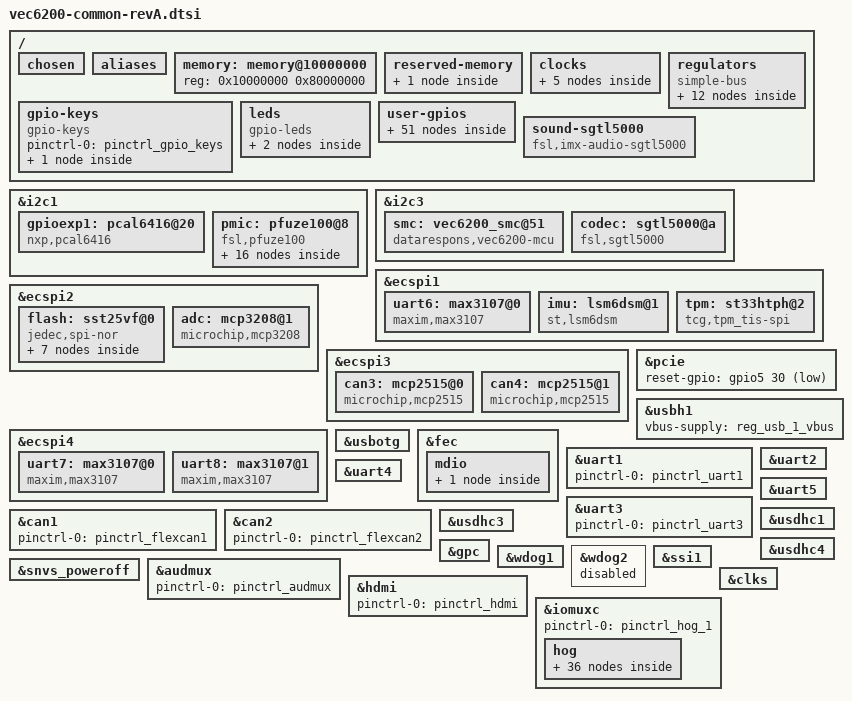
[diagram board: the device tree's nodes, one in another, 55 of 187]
/*
 * Copyright 2020 Data Respons Solutions AB
 *
 * The code contained herein is licensed under the GNU General Public
 * License. You may obtain a copy of the GNU General Public License
 * Version 2 or later at the following locations:
 *
 * http://www.opensource.org/licenses/gpl-license.html
 * http://www.gnu.org/copyleft/gpl.html
 */

#include <dt-bindings/gpio/gpio.h>
#include <dt-bindings/input/input.h>

// Issues:
// uart6 missing interrupt - must be patched
// uart6 missing reset - ok?
// flash: 8Mbit not enought --> Minimum 16Mbit. Preferred 32Mbit.
// GP_VGA_nRESET not connected

/ {	
	chosen {
		stdout-path = "serial0:115200n8";
		bootargs = "loglevel=6";
	};
	
	aliases {
		serial5 = &uart6;
		serial6 = &uart7;
		serial7 = &uart8;
		rtc0 = &smc;
		rtc1 = &snvs_rtc;
		can2 = &can3;
		can3 = &can4;
	};
	
	memory: memory@10000000 {
		reg = <0x10000000 0x80000000>;
	};
	
	reserved-memory {
		#address-cells = <1>;
		#size-cells = <1>;
		ranges;

		// Etnaviv driver requires cma region
		linux,cma {
			compatible = "shared-dma-pool";
			reusable;
			size = <0x10000000>;
			linux,cma-default;
		};
	};
	
	clocks {
		uart6_clk: osc_uart6 {
			compatible = "fixed-clock";
			#clock-cells = <0>;
			clock-frequency = <3686400>;
		};
		
		uart7_clk: osc_uart7 {
			compatible = "fixed-clock";
			#clock-cells = <0>;
			clock-frequency = <3686400>;
		};
		
		uart8_clk: osc_uart8 {
			compatible = "fixed-clock";
			#clock-cells = <0>;
			clock-frequency = <3686400>;
		};
				
		can3_clk: osc_can3 {
			compatible = "fixed-clock";
			#clock-cells = <0>;
			clock-frequency = <20000000>;
		};
		
		can4_clk: osc_can4 {
			compatible = "fixed-clock";
			#clock-cells = <0>;
			clock-frequency = <20000000>;
		};
	};
	
	regulators {
		compatible = "simple-bus";

		reg_3v3_io: 3v3_io {
			compatible = "regulator-fixed";
			regulator-name = "3v3_io";
			regulator-min-microvolt = <3300000>;
			regulator-max-microvolt = <3300000>;
		};
		
		reg_5v_io: 5v_io {
			compatible = "regulator-fixed";
			regulator-name = "5v_io";
			regulator-min-microvolt = <5000000>;
			regulator-max-microvolt = <5000000>;
		};
		
		reg_adc_vref: adc_vref {
			compatible = "regulator-fixed";
			regulator-name = "adc_vref";
			regulator-min-microvolt = <2500000>;
			regulator-max-microvolt = <2500000>;
		};
		
		reg_usb_otg_vbus: usb_otg_vbus {
			compatible = "regulator-fixed";
			pinctrl-names = "default";
			pinctrl-0 = <&pinctrl_reg_usbotg>;
			regulator-name = "usb_otg_vbus";
			regulator-min-microvolt = <5000000>;
			regulator-max-microvolt = <5000000>;
			gpio = <&gpio3 30 GPIO_ACTIVE_HIGH>;
			enable-active-high;
		};

		reg_usb_1_vbus: usb_1_vbus {
			compatible = "regulator-fixed";
			pinctrl-names = "default";
			pinctrl-0 = <&pinctrl_reg_usb1>;
			regulator-name = "usb_1_vbus";
			regulator-min-microvolt = <5000000>;
			regulator-max-microvolt = <5000000>;
			gpio = <&gpio2 0 GPIO_ACTIVE_HIGH>;
			enable-active-high;
		};
		
		reg_gps: gps {
			compatible = "regulator-fixed";
			pinctrl-names = "default";
			pinctrl-0 = <&pinctrl_reg_gps>;
			regulator-name = "gps";
			regulator-min-microvolt = <3300000>;
			regulator-max-microvolt = <3300000>;
			gpio = <&gpio2 1 GPIO_ACTIVE_HIGH>;
			enable-active-high;
			regulator-always-on;
		};
		
		reg_codec: codec {
			compatible = "regulator-fixed";
			pinctrl-names = "default";
			pinctrl-0 = <&pinctrl_reg_codec>;
			regulator-name = "codec";
			regulator-min-microvolt = <1800000>;
			regulator-max-microvolt = <1800000>;
			gpio = <&gpio6 14 GPIO_ACTIVE_HIGH>;
			enable-active-high;
		};
			
		reg_wifi: wifi {
			compatible = "regulator-fixed";
			pinctrl-names = "default";
			pinctrl-0 = <&pinctrl_reg_wifi>;
			regulator-name = "wifi";
			regulator-min-microvolt = <3300000>;
			regulator-max-microvolt = <3300000>;
			gpio = <&gpio2 2 GPIO_ACTIVE_HIGH>;
			enable-active-high;
		};
		
		reg_wifi_en: wifi_en {
			compatible = "regulator-fixed";
			pinctrl-names = "default";
			pinctrl-0 = <&pinctrl_reg_wifi_en>;
			regulator-name = "wifi_en";
			regulator-min-microvolt = <3300000>;
			regulator-max-microvolt = <3300000>;
			gpio = <&gpio2 3 GPIO_ACTIVE_HIGH>;
			enable-active-high;
			vin-supply = <&reg_wifi>;
		};
		
		reg_bt_en: bt_en {
			compatible = "regulator-fixed";
			pinctrl-names = "default";
			pinctrl-0 = <&pingctrl_reg_bt_en>;
			regulator-name = "bt_en";
			regulator-min-microvolt = <3300000>;
			regulator-max-microvolt = <3300000>;
			gpio = <&gpio2 4 GPIO_ACTIVE_HIGH>;
			enable-active-high;
			vin-supply = <&reg_wifi>;
		};
		
		reg_hdmi: hdmi {
			compatible = "regulator-fixed";
			pinctrl-names = "default";
			pinctrl-0 = <&pinctrl_reg_hdmi>;
			regulator-name = "hdmi";
			regulator-min-microvolt = <5000000>;
			regulator-max-microvolt = <5000000>;
			gpio = <&gpio6 11 GPIO_ACTIVE_HIGH>;
			enable-active-high;
			regulator-always-on;
		};
		
		reg_gps_antenna: gps_antenna {
			compatible = "regulator-fixed";
			pinctrl-names = "default";
			pinctrl-0 = <&pinctrl_reg_gps_antenna>;
			regulator-name = "gps_antenna";
			regulator-min-microvolt = <5000000>;
			regulator-max-microvolt = <5000000>;
			gpio = <&gpio6 15 GPIO_ACTIVE_HIGH>;
			enable-active-high;
			regulator-always-on;
		};
	};
	
	gpio-keys {
		compatible = "gpio-keys";
		pinctrl-names = "default";
		pinctrl-0 = <&pinctrl_gpio_keys>;

		power {
			label = "Power Button";
			gpios = <&gpio3 29 GPIO_ACTIVE_LOW>;
			gpio-key,wakeup;
			linux,code = <KEY_POWER>;
		};
	};
	
	leds {
		compatible = "gpio-leds";
		
		status-green {
			label = "status-green";
			gpios = <&gpioexp1 10 GPIO_ACTIVE_HIGH>;
		};
	
		status-red {
			label = "status-red";
			gpios = <&gpioexp1 11 GPIO_ACTIVE_HIGH>;
		};
	};

	user-gpios {	
		digital_input_1 {
			gpios = <&gpio1 1 GPIO_ACTIVE_HIGH>;
			status = "okay";
		};
		
		digital_input_2 {
			gpios = <&gpio1 2 GPIO_ACTIVE_HIGH>;
			status = "okay";
		};
		
		digital_input_3 {
			gpios = <&gpio1 5 GPIO_ACTIVE_HIGH>;
			status = "okay";
		};
		
		digital_input_4 {
			gpios = <&gpio1 6 GPIO_ACTIVE_HIGH>;
			status = "okay";
		};
		
		digital_output_sink_1 {
			gpios = <&gpio4 26 GPIO_ACTIVE_HIGH>;
			status = "okay";
			value = <0>;
		};
		
		digital_output_sink_2 {
			gpios = <&gpio4 27 GPIO_ACTIVE_HIGH>;
			status = "okay";
			value = <0>;
		};
		
		digital_output_sink_3 {
			gpios = <&gpio4 28 GPIO_ACTIVE_HIGH>;
			status = "okay";
			value = <0>;
		};

		digital_output_sink_4 {
			gpios = <&gpio4 29 GPIO_ACTIVE_HIGH>;
			status = "okay";
			value = <0>;
		};
		
		digital_output_sink_5 {
			gpios = <&gpio5 16 GPIO_ACTIVE_HIGH>;
			status = "okay";
			value = <0>;
		};
		
		digital_output_sink_6 {
			gpios = <&gpio5 17 GPIO_ACTIVE_HIGH>;
			status = "okay";
			value = <0>;
		};
		
		analog_input_1_mode {
			gpios = <&gpio1 15 GPIO_ACTIVE_HIGH>;
			status = "okay";
			value = <0>;
		};
		
		analog_input_2_mode {
			gpios = <&gpio1 14 GPIO_ACTIVE_HIGH>;
			status = "okay";
			value = <0>;
		};
		
		analog_input_3_mode {
			gpios = <&gpio1 13 GPIO_ACTIVE_HIGH>;
			status = "okay";
			value = <0>;
		};
		
		analog_input_4_mode {
			gpios = <&gpio1 12 GPIO_ACTIVE_HIGH>;
			status = "okay";
			value = <0>;
		};
		
		mcu-boot0 {
			gpios = <&gpio4 17 GPIO_ACTIVE_HIGH>;
			status = "okay";
			value = <0>;
		};
		
		mcu-status {
			gpios = <&gpio4 31 GPIO_ACTIVE_HIGH>;
			status = "okay";
			value = <0>;
		};

		mcu-reset {
			gpios = <&gpio1 4 GPIO_ACTIVE_HIGH>;
			status = "okay";
			value = <0>;
		};
		
        usb_hub_rst {
        	gpios = <&gpio7 13 GPIO_ACTIVE_LOW>;
        	status = "okay";
        	value = <0>;
		};
		
		tpm_rst {
			gpios = <&gpio4 8 GPIO_ACTIVE_LOW>;
			status = "okay";
			value = <0>;
		};
		
		flash_wp {
			gpios = <&gpio5 6 GPIO_ACTIVE_LOW>;
			status = "okay";
			value = <1>;
		};
		
		buck_5v_en {
			gpios = <&gpio5 31 GPIO_ACTIVE_HIGH>;
			status = "okay";
			value = <0>;
		};
		
		can1_en {
			gpios = <&gpioexp1 12 GPIO_ACTIVE_HIGH>;
			status = "okay";
			value = <0>;
		};

		can1_wake {
			gpios = <&gpio4 18 GPIO_ACTIVE_HIGH>;
			status = "okay";
			value = <0>;
		};
	
		can1_stb {
			gpios = <&gpio1 27 GPIO_ACTIVE_LOW>;
			status = "okay";
			value = <0>;
		};
		
		can1_err {
			gpios = <&gpioexp1 2 GPIO_ACTIVE_LOW>;
			status = "okay";
		};
		
		can1_res_en {
			gpios = <&gpio3 31 GPIO_ACTIVE_HIGH>;
			status = "okay";
			value = <0>;
		};
		
		can2_en {
			gpios = <&gpioexp1 13 GPIO_ACTIVE_HIGH>;
			status = "okay";
			value = <0>;
		};
		
		can2_wake {
			gpios = <&gpio4 19 GPIO_ACTIVE_HIGH>;
			status = "okay";
			value = <0>;
		};
	
		can2_stb {
			gpios = <&gpio4 10 GPIO_ACTIVE_LOW>;
			status = "okay";
			value = <0>;
		};
		
		can2_err {
			gpios = <&gpioexp1 3 GPIO_ACTIVE_LOW>;
			status = "okay";
		};
		
		can2_res_en {
			gpios = <&gpio1 9 GPIO_ACTIVE_HIGH>;
			status = "okay";
			value = <0>;
		};
		
		can3_en {
			gpios = <&gpioexp1 14 GPIO_ACTIVE_HIGH>;
			status = "okay";
			value = <0>;
		};
		
		can3_wake {
			gpios = <&gpio5 19 GPIO_ACTIVE_HIGH>;
			status = "okay";
			value = <0>;
		};
	
		can3_stb {
			gpios = <&gpio4 30 GPIO_ACTIVE_LOW>;
			status = "okay";
			value = <0>;
		};
		
		can3_err {
			gpios = <&gpioexp1 4 GPIO_ACTIVE_LOW>;
			status = "okay";
		};
		
		can3_res_en {
			gpios = <&gpio1 30 GPIO_ACTIVE_HIGH>;
			status = "okay";
			value = <0>;
		};
		
		can3_rst {
			gpios = <&gpio4 20 GPIO_ACTIVE_LOW>;
			status = "okay";
			value = <0>;
		};
		
		can4_en {
			gpios = <&gpioexp1 15 GPIO_ACTIVE_HIGH>;
			status = "okay";
			value = <0>;
		};
		
		can4_wake {
			gpios = <&gpio5 18 GPIO_ACTIVE_HIGH>;
			status = "okay";
			value = <0>;
		};
	
		can4_stb {
			gpios = <&gpio5 5 GPIO_ACTIVE_LOW>;
			status = "okay";
			value = <0>;
		};
		
		can4_err {
			gpios = <&gpioexp1 5 GPIO_ACTIVE_LOW>;
			status = "okay";
		};
		
		can4_res_en {
			gpios = <&gpio4 5 GPIO_ACTIVE_HIGH>;
			status = "okay";
			value = <0>;
		};
		
		can4_rst {
			gpios = <&gpio3 23 GPIO_ACTIVE_LOW>;
			status = "okay";
			value = <0>;
		};
		
		odometer {
			gpios = <&gpioexp1 0 GPIO_ACTIVE_HIGH>;
			status = "okay";
		};
		
		forward {
			gpios = <&gpioexp1 1 GPIO_ACTIVE_LOW>;
			status = "okay";
		};
		
		modem_rst {
			gpios = <&gpioexp1 6 GPIO_ACTIVE_LOW>;
			status = "okay";
			value = <0>;
		};
		
		modem_disable {
			gpios = <&gpioexp1 7 GPIO_ACTIVE_LOW>;
			status = "okay";
			value = <0>;
		};
		
		uart7_res_en {
			gpios = <&gpioexp1 8 GPIO_ACTIVE_HIGH>;
			status = "okay";
			value = <0>;
		};
		
		uart7_rst {
			gpios = <&gpio2 23 GPIO_ACTIVE_LOW>;
			status = "okay";
			value = <0>;
		};
		
		uart8_res_en {
			gpios = <&gpioexp1 9 GPIO_ACTIVE_HIGH>;
			status = "okay";
			value = <0>;
		};
		
		uart8_rst {
			gpios = <&gpio2 24 GPIO_ACTIVE_LOW>;
			status = "okay";
			value = <0>;
		};
	};

	sound-sgtl5000 {
		compatible = "fsl,imx-audio-sgtl5000";
		model = "sgtl5000";
		ssi-controller = <&ssi1>;
		audio-codec = <&codec>;
		audio-routing =
			"MIC_IN", "Mic Jack",
			"Mic Jack", "Mic Bias",
			"Line Out Jack", "LINE_OUT",
			"LINE_IN", "Line In Jack";
		mux-int-port = <1>;
		mux-ext-port = <3>;
	};
#if 0
	ch7036-lvds0 {
		compatible = "chrontel,ch7036", "panel-lvds";
		data-mapping = "jeida-24";

		width-mm = <410>; // Mandatory attribute and random googled value
		height-mm = <230>; // Mandatory attribute and random googled value
		panel-timing {
			/* 1366x768 @60Hz */
			clock-frequency = <76000000>;
			hactive = <1366>;
			vactive = <768>;
			hsync-len = <64>;
			hfront-porch = <32>;
			hback-porch = <98>;
			vsync-len = <12>;
			vfront-porch = <6>;
			vback-porch = <20>;
			hsync-active = <0>;
			vsync-active = <0>;
			de-active = <1>;
		};
			
		port {
			ch7036_in: endpoint {
				remote-endpoint = <&lvds0_out>;
			};
		};
	};
#endif
};

&i2c1 {
	clock-frequency = <100000>;
	pinctrl-names = "default", "gpio";
	pinctrl-0 = <&pinctrl_i2c1>;
	pinctrl-1 = <&pinctrl_i2c1_gpio>;
	scl-gpios = <&gpio5 27 (GPIO_ACTIVE_LOW|GPIO_OPEN_DRAIN)>;
	sda-gpios = <&gpio5 26 (GPIO_ACTIVE_LOW|GPIO_OPEN_DRAIN)>;
	status = "okay";

	gpioexp1: pcal6416@20 {
		compatible = "nxp,pcal6416";
		reg = <0x20>;
		pinctrl-names = "default";
		pinctrl-0 = <&pinctrl_pcal6416>;
		interrupt-parent = <&gpio2>;
		interrupts = <5 IRQ_TYPE_EDGE_FALLING>;
		reset-gpios = <&gpio2 7 GPIO_ACTIVE_LOW>;
		interrupt-controller;
		#interrupt-cells = <2>;
		gpio-controller;
		#gpio-cells = <2>;
	};
	
	pmic: pfuze100@8 {
		compatible = "fsl,pfuze100";
		reg = <0x08>;
		pinctrl-names = "default";
		pinctrl-0 = <&pinctrl_pmic>;
		interrupt-parent = <&gpio6>;
		interrupts = <10 IRQ_TYPE_EDGE_FALLING>;

		regulators {
			sw1a_reg: sw1ab {
				regulator-min-microvolt = <300000>;
				regulator-max-microvolt = <1875000>;
				regulator-boot-on;
				regulator-always-on;
				regulator-ramp-delay = <6250>;
			};

			sw1c_reg: sw1c {
				regulator-min-microvolt = <300000>;
				regulator-max-microvolt = <1875000>;
				regulator-boot-on;
				regulator-always-on;
				regulator-ramp-delay = <6250>;
			};

			sw2_reg: sw2 {
				regulator-min-microvolt = <800000>;
				regulator-max-microvolt = <3300000>;
				regulator-boot-on;
				regulator-always-on;
				regulator-ramp-delay = <6250>;
			};

			sw3a_reg: sw3a {
				regulator-min-microvolt = <400000>;
				regulator-max-microvolt = <1975000>;
				regulator-boot-on;
				regulator-always-on;
			};

			sw3b_reg: sw3b {
				regulator-min-microvolt = <400000>;
				regulator-max-microvolt = <1975000>;
				regulator-boot-on;
				regulator-always-on;
			};

			sw4_reg: sw4 {
				regulator-min-microvolt = <800000>;
				regulator-max-microvolt = <3300000>;
			};

			swbst_reg: swbst {
				regulator-min-microvolt = <5000000>;
				regulator-max-microvolt = <5150000>;
			};

			snvs_reg: vsnvs {
				regulator-min-microvolt = <1000000>;
				regulator-max-microvolt = <3000000>;
				regulator-boot-on;
				regulator-always-on;
			};

			vref_reg: vrefddr {
				regulator-boot-on;
				regulator-always-on;
			};

			vgen1_reg: vgen1 {
				regulator-min-microvolt = <800000>;
				regulator-max-microvolt = <1550000>;
			};

			vgen2_reg: vgen2 {
				regulator-min-microvolt = <800000>;
				regulator-max-microvolt = <1550000>;
			};

			vgen3_reg: vgen3 {
				regulator-min-microvolt = <1800000>;
				regulator-max-microvolt = <3300000>;
			};

			vgen4_reg: vgen4 {
				regulator-min-microvolt = <1800000>;
				regulator-max-microvolt = <3300000>;
				regulator-always-on;
			};

			vgen5_reg: vgen5 {
				regulator-min-microvolt = <1800000>;
				regulator-max-microvolt = <3300000>;
				regulator-always-on;
			};

			vgen6_reg: vgen6 {
				regulator-min-microvolt = <1800000>;
				regulator-max-microvolt = <3300000>;
				regulator-always-on;
			};
		};
	};
};

&i2c3 {
	clock-frequency = <100000>;
	pinctrl-names = "default", "gpio";
	pinctrl-0 = <&pinctrl_i2c3>;
	pinctrl-1 = <&pinctrl_i2c3_gpio>;
	scl-gpios = <&gpio1 3 (GPIO_ACTIVE_LOW|GPIO_OPEN_DRAIN)>;
	sda-gpios = <&gpio7 11 (GPIO_ACTIVE_LOW|GPIO_OPEN_DRAIN)>;
	status = "okay";

	smc: vec6200_smc@51 {
		compatible = "datarespons,vec6200-mcu";
		reg = <0x51>;
		interrupt-parent = <&gpio5>;
		interrupts = <15 IRQ_TYPE_EDGE_FALLING>;
		//FIXME: additional GPIO
		smc-gpio-names = "gpio_dc_on", "gpio_can_on", "gpi_ignition", "gpi_wakeup";
		smc-gpio-input = <0 0 1 1>;
		has-rtc;
	};
	
	codec: sgtl5000@a {
		compatible = "fsl,sgtl5000";
		reg = <0x0a>;
		#sound-dai-cells = <0>;
		clocks = <&clks IMX6QDL_CLK_CKO>;
		micbias-resistor-k-ohms = <2>;
		micbias-voltage-m-volts = <1250>;
		VDDA-supply = <&reg_3v3_io>;
		VDDIO-supply = <&reg_3v3_io>;
		VDDD-supply = <&reg_codec>;
	};
	
	//FIXME: CH7036
};

&ecspi1 {
	fsl,cpi-num-chipselects = <3>;
	cs-gpios = 	<&gpio2 25 GPIO_ACTIVE_LOW>,
				<&gpio3 19 GPIO_ACTIVE_LOW>,
				<&gpio4 11 GPIO_ACTIVE_LOW>;
	pinctrl-names = "default";
	pinctrl-0 = <&pinctrl_ecspi1>;
	status = "okay";
	
	uart6: max3107@0 {
		compatible = "maxim,max3107";
		reg = <0>;
		spi-max-frequency = <26000000>;
		clocks = <&uart6_clk>;
		clock-names = "osc";
		//interrupt-parent = <&gpio3>; //FIXME: NO IRQ
		//interrupts = <7 IRQ_TYPE_LEVEL_LOW>;
	};
	
	imu: lsm6dsm@1 {
		reg = <1>;
		compatible = "st,lsm6dsm";
		spi-max-frequency = <10000000>;
		interrupt-parent = <&gpio5>;
		interrupts = <7 IRQ_TYPE_EDGE_RISING>, <8 IRQ_TYPE_EDGE_RISING>;
	};
	
	tpm: st33htph@2 {
		reg = <2>;
		compatible = "tcg,tpm_tis-spi";
		spi-max-frequency = <10000000>;
		interrupt-parent = <&gpio5>;
		interrupts = <14 IRQ_TYPE_EDGE_FALLING>;
	};
};

&ecspi2 {
	fsl,spi-num-chipselects = <2>;
	cs-gpios =	<&gpio5 12 GPIO_ACTIVE_LOW>,
				<&gpio5 9 GPIO_ACTIVE_LOW>;
	pinctrl-names = "default";
	pinctrl-0 = <&pinctrl_ecspi2>;
	status = "okay";

	flash: sst25vf@0 {
		#address-cells = <1>;
		compatible = "jedec,spi-nor";
		spi-max-frequency = <25000000>;
		reg = <0>;
		
		partitions {
			compatible = "fixed-partitions";
			#address-cells = <1>;
			#size-cells = <1>;
			
			spl@0 {
				label = "spl";
				reg = <0x0 0x20000>;
			};
			
			u-boot@20000 {
				label = "u-boot";
				reg = <0x20000 0x90000>;
			};
		
			system_a@B0000 {
				label = "system_a";
				reg = <0xB0000 0x10000>;
			};
			
			system_b@C0000 {
				label = "system_b";
				reg = <0xC0000 0x10000>;
			};
				
			user_a@D0000 {
				label = "user_a";
				reg = <0xD0000 0x10000>;
			};
			
			user_b@E0000 {
				label = "user_b";
				reg = <0xE0000 0x10000>;
			};
		};
	};
	
	adc: mcp3208@1 {
		reg = <1>;
		compatible = "microchip,mcp3208";
		spi-max-frequency = <1000000>;
		vref-supply = <&reg_adc_vref>;
	};
};

&ecspi3 {
	fsl,cpi-num-chipselects = <2>;
	cs-gpios = 	<&gpio4 24 GPIO_ACTIVE_LOW>,
				<&gpio4 25 GPIO_ACTIVE_LOW>;
	pinctrl-names = "default";
	pinctrl-0 = <&pinctrl_ecspi3>;
	status = "okay";
	
	can3: mcp2515@0 {
		compatible = "microchip,mcp2515";
		spi-max-frequency = <10000000>;
		reg = <0>;
		clocks = <&can3_clk>;
		interrupt-parent = <&gpio3>;
		interrupts = <26 IRQ_TYPE_EDGE_FALLING>;
		vdd-supply = <&reg_5v_io>;
		xceiver-supply = <&reg_5v_io>;
	};
	
	can4: mcp2515@1 {
		compatible = "microchip,mcp2515";
		spi-max-frequency = <10000000>;
		reg = <1>;
		clocks = <&can4_clk>;
		interrupt-parent = <&gpio3>;
		interrupts = <27 IRQ_TYPE_EDGE_FALLING>;
		vdd-supply = <&reg_5v_io>;
		xceiver-supply = <&reg_5v_io>;
	};
};

&ecspi4 {
	fsl,cpi-num-chipselects = <2>;
	cs-gpios = 	<&gpio3 20 GPIO_ACTIVE_LOW>,
				<&gpio5 2 GPIO_ACTIVE_LOW>;
	pinctrl-names = "default";
	pinctrl-0 = <&pinctrl_ecspi4>;
	status = "okay";
	
	uart7: max3107@0 {
		compatible = "maxim,max3107";
		reg = <0>;
		spi-max-frequency = <26000000>;
		clocks = <&uart7_clk>;
		clock-names = "osc";
		interrupt-parent = <&gpio1>;
		interrupts = <11 IRQ_TYPE_EDGE_FALLING>;
	};
	
	uart8: max3107@1 {
		compatible = "maxim,max3107";
		reg = <1>;
		spi-max-frequency = <26000000>;
		clocks = <&uart8_clk>;
		clock-names = "osc";
		interrupt-parent = <&gpio1>;
		interrupts = <10 IRQ_TYPE_EDGE_FALLING>;
	};
};

&pcie {
	reset-gpio = <&gpio5 30 GPIO_ACTIVE_LOW>;
	status = "okay";
};

&usbh1 {
	vbus-supply = <&reg_usb_1_vbus>;
	status = "okay";		
};

&usbotg {
	vbus-supply = <&reg_usb_otg_vbus>;
	pinctrl-names = "default";
	pinctrl-0 = <&pinctrl_usbotg>;
	vbus-supply = <&reg_usb_otg_vbus>;
	over-current-active-low;
	status = "okay";
};

&fec {
	pinctrl-names = "default";
	pinctrl-0 = <&pinctrl_enet0>;
	phy-mode = "rgmii";
	status = "okay";
	
	phy-handle = <&enet0_phy>;
	
	mdio {
		#address-cells = <1>;
		#size-cells = <0>;
		
		enet0_phy: ar8033@0 {
			compatible = "ethernet-phy-ieee802.3-c22";
			reg = <0>;
			max-speed = <100>;
			interrupt-parent = <&gpio1>;
			interrupts = <26 IRQ_TYPE_EDGE_FALLING>;
		};
	};
};

&uart1 {
	pinctrl-names = "default";
	pinctrl-0 = <&pinctrl_uart1>;
	status = "okay";
};

&uart2 {
	pinctrl-names = "default";
	pinctrl-0 = <&pinctrl_uart2>;
	uart-has-rtscts;
	status = "okay";
};

&uart3 {
	pinctrl-names = "default";
	pinctrl-0 = <&pinctrl_uart3>;
	status = "okay";
};

&uart4 {
	pinctrl-names = "default";
	pinctrl-0 = <&pinctrl_uart4>;
	uart-has-rtscts;
	status = "okay";
};

&uart5 {
	pinctrl-names = "default";
	pinctrl-0 = <&pinctrl_uart5>;
	uart-has-rtscts;
	status = "okay";
};

&can1 {
	pinctrl-names = "default";
	pinctrl-0 = <&pinctrl_flexcan1>;
	status = "okay";
};

&can2 {
	pinctrl-names = "default";
	pinctrl-0 = <&pinctrl_flexcan2>;
	status = "okay";
};

&usdhc1 {
	pinctrl-names = "default";
	pinctrl-0 = <&pinctrl_usdhc1>;
	bus-width = <4>;
	broken-cd;
	no-1-8-v;
	keep-power-in-suspend;
	enable-sdio-wakeup;
	status = "okay";
};

&usdhc3 {
	pinctrl-names = "default";
	pinctrl-0 = <&pinctrl_usdhc3>;
	bus-width = <8>;
	non-removable;
	no-1-8-v;
	keep-power-in-suspend;
	status = "okay";
};

&usdhc4 {
	pinctrl-names = "default";
	pinctrl-0 = <&pinctrl_usdhc4>;
	bus-width = <4>;
	non-removable;
	no-1-8-v;
	keep-power-in-suspend;
	cap-power-off-card;
	max-frequency = <25000000>;
	#address-cells = <1>;
	#size-cells = <0>;
	status = "okay";
	vmmc-supply = <&reg_wifi_en>;
	
	// FIXME wifi module
};

&gpc {
	fsl,ldo-bypass = <0>;
	fsl,wdog-reset = <1>;
};

&wdog1 {
	status = "okay";
};

&wdog2 {
	status = "disabled";
};

&snvs_poweroff {
	status = "okay";
};

&ssi1 {
	status = "okay";
};

&audmux {
	pinctrl-names = "default";
	pinctrl-0 = <&pinctrl_audmux>;
	status = "okay";
};

&hdmi {
	pinctrl-names = "default";
	pinctrl-0 = <&pinctrl_hdmi>;
	status = "okay";
};
#if 0
&ldb {
	status = "okay";

	lvds-channel@0 {
		status = "okay";

		port@4 {
			reg = <4>;

			lvds0_out: endpoint {
				remote-endpoint = <&ch7036_in>;
			};
		};
	};
};
#endif
//FIXME: Clocks needed..?
&clks {
	assigned-clocks =	<&clks IMX6QDL_CLK_LDB_DI0_SEL>,
			  			<&clks IMX6QDL_CLK_LDB_DI1_SEL>;
	assigned-clock-parents = <&clks IMX6QDL_CLK_PLL3_USB_OTG>,
							 <&clks IMX6QDL_CLK_PLL3_USB_OTG>;
};

&iomuxc {
	pinctrl-names = "default";
	pinctrl-0 = <&pinctrl_hog_1>;
	
	hog {
		pinctrl_hog_1: hoggrp-1 {
			fsl,pins = <
				/* pins not captured by driver */
				MX6QDL_PAD_DISP0_DAT21__GPIO5_IO15	0x1b0b1 /* GPO-nINT--MCU */
				MX6QDL_PAD_CSI0_DAT12__GPIO5_IO30	0x02060 /* GP-PCIE_PWR_nEN */
				MX6QDL_PAD_GPIO_0__CCM_CLKO1		0x130b0 /* AUD_MCLK */
			
				/* not-connected */
				//MX6QDL_PAD_ENET_TXD1__GPIO1_IO29	0x02060 /* GP_VGA_nRESET */

				/* unknown usage */
				//MX6QDL_PAD_NANDF_D6__GPIO2_IO06		0x02060 /* GP--BT_HOST_WAKE */

				/* user gpio */
				MX6QDL_PAD_GPIO_18__GPIO7_IO13		0x02060 /* HUB1_RESET# */
				MX6QDL_PAD_SD2_DAT0__GPIO1_IO15		0x02060 /* EN--4-20mA_ANI_1 */
				// FIXME: imx_pinctrl_set_state() never returns if below pin defined 
				MX6QDL_PAD_SD2_DAT1__GPIO1_IO14		0x02060 /* EN--4-20mA_ANI_2 */
				MX6QDL_PAD_SD2_DAT2__GPIO1_IO13		0x02060 /* EN--4-20mA_ANI_3 */
				MX6QDL_PAD_SD2_DAT3__GPIO1_IO12		0x02060 /* EN--4-20mA_ANI_4 */
				MX6QDL_PAD_GPIO_1__GPIO1_IO01		0x1b0b1 /* GPI_1--PCA */
				MX6QDL_PAD_GPIO_2__GPIO1_IO02		0x1b0b1 /* GPI_2--PCA */
				MX6QDL_PAD_GPIO_5__GPIO1_IO05		0x1b0b1 /* GPI_3--PCA */
				MX6QDL_PAD_GPIO_6__GPIO1_IO06		0x1b0b1 /* GPI_4--PCA */
				MX6QDL_PAD_DISP0_DAT5__GPIO4_IO26	0X02060 /* GPO5_IN--CPU */
				MX6QDL_PAD_DISP0_DAT6__GPIO4_IO27	0x02060 /* GPO6_IN--CPU */
				MX6QDL_PAD_DISP0_DAT7__GPIO4_IO28 	0x02060 /* GPO7_IN--CPU */
				MX6QDL_PAD_DISP0_DAT8__GPIO4_IO29	0x02060 /* GPO8_IN--CPU */
				MX6QDL_PAD_DISP0_DAT22__GPIO5_IO16	0x02060 /* GPO9_IN--CPU */
				MX6QDL_PAD_DISP0_DAT23__GPIO5_IO17	0x02060 /* GPO10_IN--CPU */
				MX6QDL_PAD_GPIO_4__GPIO1_IO04		0x02060 /* GP-NRST--MCU1 */
				MX6QDL_PAD_DI0_PIN15__GPIO4_IO17	0X02060 /* GP-MCU_BOOT0_SET */
				MX6QDL_PAD_DISP0_DAT10__GPIO4_IO31	0x02060 /* GP-Status--CPU */
				MX6QDL_PAD_KEY_COL1__GPIO4_IO08		0x02060 /* GP-nRESET--TPM */
				MX6QDL_PAD_DISP0_DAT12__GPIO5_IO06	0x0a060 /* SPI_ECSPI_WP */
				MX6QDL_PAD_DI0_PIN2__GPIO4_IO18		0x02060 /* GP_CAN1_WAKE */
				MX6QDL_PAD_ENET_RXD0__GPIO1_IO27	0x02060 /* GP_CAN1_STB */
				MX6QDL_PAD_EIM_D31__GPIO3_IO31		0x02060 /* GP_CAN1_RES_EN */	
				MX6QDL_PAD_DI0_PIN3__GPIO4_IO19		0x02060 /* GP_CAN2_WAKE */
				MX6QDL_PAD_KEY_COL2__GPIO4_IO10		0x02060 /* GP_CAN2_STB */
				MX6QDL_PAD_GPIO_9__GPIO1_IO09		0x02060 /* GP_CAN2_RES_EN */
				MX6QDL_PAD_CSI0_MCLK__GPIO5_IO19	0x02060 /* GP_CAN3_WAKE */
				MX6QDL_PAD_DISP0_DAT9__GPIO4_IO30	0x02060 /* GP_CAN3_STB */
				MX6QDL_PAD_ENET_TXD0__GPIO1_IO30	0x02060 /* GP_CAN3_RES_EN */
				MX6QDL_PAD_DI0_PIN4__GPIO4_IO20		0x02060 /* CAN3_RESET--CPU */
				MX6QDL_PAD_CSI0_PIXCLK__GPIO5_IO18	0x02060 /* GP_CAN4_WAKE */
				MX6QDL_PAD_DISP0_DAT11__GPIO5_IO05	0x02060 /* GP_CAN4_STB */
				MX6QDL_PAD_GPIO_19__GPIO4_IO05		0x02060 /* GP_CAN4_RES_EN */
				MX6QDL_PAD_EIM_D23__GPIO3_IO23		0x02060 /* CAN4_RESET--CPU */
				MX6QDL_PAD_CSI0_DAT13__GPIO5_IO31	0x02060 /* GP-EN--BUCK_5V--CPU */
				MX6QDL_PAD_EIM_CS0__GPIO2_IO23		0x02060 /* RST--UARTA */
				MX6QDL_PAD_EIM_CS1__GPIO2_IO24		0x02060 /* RST--UARTB */
			>;
		};
		
		pinctrl_i2c1: i2c1grp {
			fsl,pins = <
				MX6QDL_PAD_CSI0_DAT8__I2C1_SDA		0x4001b8b1
				MX6QDL_PAD_CSI0_DAT9__I2C1_SCL		0x4001b8b1
			>;
		};
		
		pinctrl_i2c1_gpio: i2c1gpiogrp {
			fsl,pins = <
				MX6QDL_PAD_CSI0_DAT8__GPIO5_IO26	0x4001b8b1
				MX6QDL_PAD_CSI0_DAT9__GPIO5_IO27	0x4001b8b1
			>;
		};
				
		pinctrl_i2c3: i2c3grp {
			fsl,pins = <
				MX6QDL_PAD_GPIO_16__I2C3_SDA		0x4001b8b1
				MX6QDL_PAD_GPIO_3__I2C3_SCL			0x4001b8b1
			>;
		};
		
		pinctrl_i2c3_gpio: i2c3gpiogrp {
			fsl,pins = <
				MX6QDL_PAD_GPIO_16__GPIO7_IO11		0x4001b8b1
				MX6QDL_PAD_GPIO_3__GPIO1_IO03		0x4001b8b1
			>;
		};
		
		pinctrl_ecspi1: ecspi1grp {
			fsl,pins = <
				MX6QDL_PAD_EIM_D16__ECSPI1_SCLK		0x000100b1
				MX6QDL_PAD_EIM_D17__ECSPI1_MISO		0x000100b1
				MX6QDL_PAD_EIM_D18__ECSPI1_MOSI		0x000100b1
				MX6QDL_PAD_EIM_OE__GPIO2_IO25		0x0001b0b1 /* SPI1_SS--CPU */
				MX6QDL_PAD_EIM_D19__GPIO3_IO19		0x0001b0b1 /* SPI1_SS1--CPU */
				MX6QDL_PAD_DISP0_DAT13__GPIO5_IO07	0x0001b0b1 /* INT1_ACC--CPU */
				MX6QDL_PAD_DISP0_DAT14__GPIO5_IO08	0x0001b0b1 /* INT2_ACC--CPU */
				MX6QDL_PAD_KEY_ROW2__GPIO4_IO11		0X0001b0b1 /* SPI1_SS2--CPU */
				MX6QDL_PAD_DISP0_DAT20__GPIO5_IO14	0x0001b0b1 /* GP-nINT--TPM */
			>;
		};
		
		pinctrl_ecspi2: ecspi2grp {
			fsl,pins = <
				MX6QDL_PAD_DISP0_DAT19__ECSPI2_SCLK	0x000100b1
				MX6QDL_PAD_DISP0_DAT17__ECSPI2_MISO	0x000100b1
				MX6QDL_PAD_DISP0_DAT16__ECSPI2_MOSI	0x000100b1
				MX6QDL_PAD_DISP0_DAT18__GPIO5_IO12	0x0001b0b1 /* SPI2_SS0--CPU */
				MX6QDL_PAD_DISP0_DAT15__GPIO5_IO09	0x0001b0b1 /* SPI2_SS1--CPU */
				
			>;
		};
		
		pinctrl_ecspi3: ecspi3grp {
			fsl,pins = <
				MX6QDL_PAD_DISP0_DAT0__ECSPI3_SCLK	0x000100b1
				MX6QDL_PAD_DISP0_DAT2__ECSPI3_MISO	0x000100b1
				MX6QDL_PAD_DISP0_DAT1__ECSPI3_MOSI	0x000100b1
				MX6QDL_PAD_DISP0_DAT3__GPIO4_IO24	0x000100b1 /* SPI3_SS0--CPU */
				MX6QDL_PAD_EIM_D26__GPIO3_IO26		0x0001b0b1 /* CAN3_INT--CPU */
				MX6QDL_PAD_DISP0_DAT4__GPIO4_IO25	0x000100b1 /* SPI3_SS1--CPU */
				MX6QDL_PAD_EIM_D27__GPIO3_IO27		0x0001b0b1 /* CAN4_INT--CPU */

			>;
		};
		
		pinctrl_ecspi4: ecspi4grp {
			fsl,pins = <
				MX6QDL_PAD_EIM_D21__ECSPI4_SCLK		0x000100b1
				MX6QDL_PAD_EIM_D22__ECSPI4_MISO		0x000100b1
				MX6QDL_PAD_EIM_D28__ECSPI4_MOSI		0x000100b1
				MX6QDL_PAD_EIM_D20__GPIO3_IO20		0x000100b1 /* SPI4_SS0--CPU */
				MX6QDL_PAD_SD2_CMD__GPIO1_IO11		0x0001b0b1 /* IRQ--UARTA--CPU */
				MX6QDL_PAD_EIM_A25__GPIO5_IO02		0x000100b1 /* SPI4_SS1--CPU */
				MX6QDL_PAD_SD2_CLK__GPIO1_IO10		0x0001b0b1 /* IRQ--UARTB--CPU */
			>;
		};
		
		pinctrl_uart1: uart1grp {
			fsl,pins = <
				MX6QDL_PAD_CSI0_DAT10__UART1_TX_DATA	0x1b0b1
				MX6QDL_PAD_CSI0_DAT11__UART1_RX_DATA	0x1b0b1
			>;
		};
		
		pinctrl_uart2: uart2grp {
			fsl,pins = <
				MX6QDL_PAD_SD4_DAT7__UART2_TX_DATA		0x1b0b1
				MX6QDL_PAD_SD4_DAT4__UART2_RX_DATA		0x1b0b1
				MX6QDL_PAD_SD4_DAT5__UART2_RTS_B		0x1b0b1
				MX6QDL_PAD_SD4_DAT6__UART2_CTS_B		0x1b0b1
			>;
		};
		
		pinctrl_uart3: uart3grp {
			fsl,pins = <
				MX6QDL_PAD_EIM_D24__UART3_TX_DATA		0x1b0b1
				MX6QDL_PAD_EIM_D25__UART3_RX_DATA		0x1b0b1
			>;
		};
		
		pinctrl_uart4: uart4grp {
			fsl,pins = <
				MX6QDL_PAD_KEY_COL0__UART4_TX_DATA		0x1b0b1
				MX6QDL_PAD_KEY_ROW0__UART4_RX_DATA		0x1b0b1
				MX6QDL_PAD_CSI0_DAT16__UART4_RTS_B		0x1b0b1
				MX6QDL_PAD_CSI0_DAT17__UART4_CTS_B		0x1b0b1
			>;
		};
		
		pinctrl_uart5: uart5grp {
			fsl,pins = <
				MX6QDL_PAD_CSI0_DAT14__UART5_TX_DATA	0x1b0b1
				MX6QDL_PAD_CSI0_DAT15__UART5_RX_DATA	0x1b0b1
				MX6QDL_PAD_CSI0_DAT18__UART5_RTS_B		0x1b0b1
				MX6QDL_PAD_CSI0_DAT19__UART5_CTS_B		0x1b0b1
			>;
		};
		
		pinctrl_usdhc1: usdhc1grp {
			fsl,pins = <
				MX6QDL_PAD_SD1_CMD__SD1_CMD		0x17059
				MX6QDL_PAD_SD1_CLK__SD1_CLK		0x17059
				MX6QDL_PAD_SD1_DAT0__SD1_DATA0	0x17059
				MX6QDL_PAD_SD1_DAT1__SD1_DATA1	0x17059
				MX6QDL_PAD_SD1_DAT2__SD1_DATA2	0x17059
				MX6QDL_PAD_SD1_DAT3__SD1_DATA3	0x17059
			>;
		};
		
		pinctrl_usdhc3: usdhc3grp {
			fsl,pins = <
				MX6QDL_PAD_SD3_CMD__SD3_CMD		0x17059
				MX6QDL_PAD_SD3_CLK__SD3_CLK		0x17059
				MX6QDL_PAD_SD3_DAT0__SD3_DATA0	0x17059
				MX6QDL_PAD_SD3_DAT1__SD3_DATA1	0x17059
				MX6QDL_PAD_SD3_DAT2__SD3_DATA2	0x17059
				MX6QDL_PAD_SD3_DAT3__SD3_DATA3	0x17059
				MX6QDL_PAD_SD3_DAT4__SD3_DATA4	0x17059
				MX6QDL_PAD_SD3_DAT5__SD3_DATA5	0x17059
				MX6QDL_PAD_SD3_DAT6__SD3_DATA6	0x17059
				MX6QDL_PAD_SD3_DAT7__SD3_DATA7	0x17059
				MX6QDL_PAD_SD3_RST__SD3_RESET	0x17059
			>;
		};
		
		pinctrl_usdhc4: usdhc4grp {
			fsl,pins = <
				MX6QDL_PAD_SD4_CMD__SD4_CMD		0x17059
				MX6QDL_PAD_SD4_CLK__SD4_CLK		0x17059
				MX6QDL_PAD_SD4_DAT0__SD4_DATA0	0x17059
				MX6QDL_PAD_SD4_DAT1__SD4_DATA1	0x17059
				MX6QDL_PAD_SD4_DAT2__SD4_DATA2	0x17059
				MX6QDL_PAD_SD4_DAT3__SD4_DATA3	0x17059
			>;
		};
		
		pinctrl_enet0: enet0grp {
			fsl,pins = <
				MX6QDL_PAD_RGMII_TXC__RGMII_TXC			0x1b0b0
				MX6QDL_PAD_RGMII_TD0__RGMII_TD0			0x1b0b0
				MX6QDL_PAD_RGMII_TD1__RGMII_TD1			0x1b0b0
				MX6QDL_PAD_RGMII_TD2__RGMII_TD2			0x1b0b0
				MX6QDL_PAD_RGMII_TD3__RGMII_TD3			0x1b0b0
				MX6QDL_PAD_RGMII_TX_CTL__RGMII_TX_CTL	0x1b0b0
				MX6QDL_PAD_RGMII_RXC__RGMII_RXC			0x1b0b0
				MX6QDL_PAD_RGMII_RD0__RGMII_RD0			0x1b0b0
				MX6QDL_PAD_RGMII_RD1__RGMII_RD1			0x1b0b0
				MX6QDL_PAD_RGMII_RD2__RGMII_RD2			0x1b0b0
				MX6QDL_PAD_RGMII_RD3__RGMII_RD3			0x1b0b0
				MX6QDL_PAD_RGMII_RX_CTL__RGMII_RX_CTL	0x1b0b0
				MX6QDL_PAD_ENET_REF_CLK__ENET_TX_CLK	0x40000000
				MX6QDL_PAD_ENET_MDC__ENET_MDC			0x1b0b0
				MX6QDL_PAD_ENET_MDIO__ENET_MDIO			0x1b0b0
				MX6QDL_PAD_ENET_CRS_DV__GPIO1_IO25		0x1b0b0 /* RGMII--CPU_nRST */
				MX6QDL_PAD_ENET_RXD1__GPIO1_IO26		0x1b0b0 /* GP--ETH_INT */
				MX6QDL_PAD_ENET_TX_EN__GPIO1_IO28		0x1b0b0 /* GP--ETH_WAKE */
			>;
		};
		
		pinctrl_usbotg: usbotggrp {
			fsl,pins = <
				MX6QDL_PAD_ENET_RX_ER__USB_OTG_ID	0x17059 /* USB_OTG_ID */
				MX6QDL_PAD_KEY_ROW1__GPIO4_IO09		0x1b0b0 /* USB_OTG_OC - active low */
			>;
		};
		
		pinctrl_pcie: pciegrp {
			fsl,pins = <
				MX6QDL_PAD_GPIO_17__GPIO7_IO12		0x2060 /* PCIE_RST# */
			>;
		};
		
		pinctrl_reg_usb1: regusb1grp {
			fsl,pins = <
				MX6QDL_PAD_NANDF_D0__GPIO2_IO00		0x2060 /* USB_HUB_EN */
			>;
		};
		
		pinctrl_reg_usbotg: regusbotggrp {
			fsl,pins = <
				MX6QDL_PAD_EIM_D30__GPIO3_IO30		0x2060 /* USB_OTG_PWR_EN */
			>;
		};
		
		pinctrl_reg_gps: reggpsgrp {
			fsl,pins = <
				MX6QDL_PAD_NANDF_D1__GPIO2_IO01		0x2060 /* GPS_PW_EN */
			>;
		};
		
		pinctrl_reg_codec: regcodecgrp {
			fsl,pins = <
				MX6QDL_PAD_NANDF_CS1__GPIO6_IO14 	0x2060 /* CODEC_EN */
			>;
		};
		
		pinctrl_reg_wifi:  regwifigrp {
			fsl,pins = <
				MX6QDL_PAD_NANDF_D2__GPIO2_IO02		0x2060 /* GP-WIFI_PWR_nEN */
			>;
		};
		
		pinctrl_reg_wifi_en: regwifiengrp {
			fsl,pins = <
				MX6QDL_PAD_NANDF_D3__GPIO2_IO03		0x02060 /* WL_REG_ON */
			>;
		};
		
		pingctrl_reg_bt_en: regbtengrp {
			fsl,pins = <
				MX6QDL_PAD_NANDF_D4__GPIO2_IO04		0x02060 /* BT_REG_ON */
			>;
		};
		
		pinctrl_reg_hdmi: reghdmigrp {
			fsl,pins = <
				MX6QDL_PAD_NANDF_CS0__GPIO6_IO11	0x2060 /* HDMIT_EN */
			>;
		};

		pinctrl_reg_gps_antenna: gpsantennagrp {
			fsl,pins = <
				MX6QDL_PAD_NANDF_CS2__GPIO6_IO15	0x02060 /* GP-EN_PWR--ANT_GPS */
			>;
		};
		
		pinctrl_flexcan1: flexcan1grp {
			fsl,pins = <
				MX6QDL_PAD_GPIO_7__FLEXCAN1_TX		0x1b0b1
				MX6QDL_PAD_GPIO_8__FLEXCAN1_RX		0X1b0b1
			>;
		};	
		
		pinctrl_flexcan2: flexcan2grp {
			fsl,pins = <
				MX6QDL_PAD_KEY_COL4__FLEXCAN2_TX	0x1b0b1
				MX6QDL_PAD_KEY_ROW4__FLEXCAN2_RX	0X1b0b1
			>;
		};		
		
		pinctrl_hdmi: hdmigrp {
			fsl,pins = <
				MX6QDL_PAD_KEY_ROW3__HDMI_TX_DDC_SDA	0x4001b8b1
				MX6QDL_PAD_KEY_COL3__HDMI_TX_DDC_SCL	0x4001b8b1
			>;
		};
		
		pinctrl_pmic: pmicgrp {
			fsl,pins = <
				MX6QDL_PAD_NANDF_RB0__GPIO6_IO10	0x1b0b1 /* PMIC_INT_B */
			>;
		};
		
		pinctrl_audmux: audmuxgrp {
			fsl,pins = <
				MX6QDL_PAD_CSI0_DAT4__AUD3_TXC		0x130b0	/* I2S--AUD3_TXC */
				MX6QDL_PAD_CSI0_DAT5__AUD3_TXD		0x130b0 /* I2S--AUD3_TXD */
				MX6QDL_PAD_CSI0_DAT6__AUD3_TXFS		0x130b0 /* I2S--AUD3_TXFS */
				MX6QDL_PAD_CSI0_DAT7__AUD3_RXD		0x130b0 /* I2S--AUD3_RXD */
			>;
		};
		
		pinctrl_gpio_keys: gpio_keysgrp {
			fsl,pins = <
				MX6QDL_PAD_EIM_D29__GPIO3_IO29		0x1b000 /* PWR_BTN_SNS / GPO-POWER_BTN */
			>;
		};
		
		pinctrl_pcal6416: pcal6416grp {
			fsl,pins = <
				MX6QDL_PAD_NANDF_D7__GPIO2_IO07		0x2060 /* IO_RESET_N_--CPU */
				MX6QDL_PAD_NANDF_D5__GPIO2_IO05		0x1b0b1 /* IO_INT_N--CPU */
			>;
		};
	};
};
